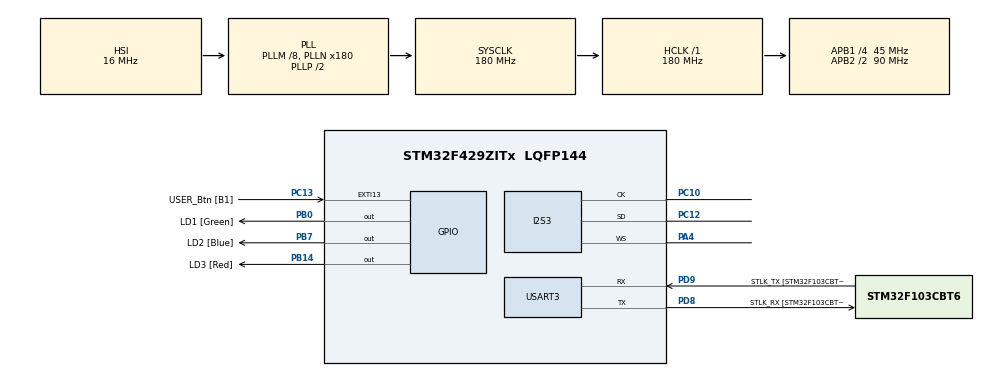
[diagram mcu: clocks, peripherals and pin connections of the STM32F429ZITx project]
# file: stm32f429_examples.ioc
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Dma.Request0=SPI3_RX
Dma.SPI3_RX.0.Direction=DMA_PERIPH_TO_MEMORY
Dma.SPI3_RX.0.FIFOMode=DMA_FIFOMODE_DISABLE
Dma.SPI3_RX.0.Instance=DMA1_Stream0
Dma.SPI3_RX.0.MemDataAlignment=DMA_MDATAALIGN_HALFWORD
Dma.SPI3_RX.0.MemInc=DMA_MINC_ENABLE
Dma.SPI3_RX.0.Mode=DMA_CIRCULAR
Dma.SPI3_RX.0.PeriphDataAlignment=DMA_PDATAALIGN_HALFWORD
Dma.SPI3_RX.0.PeriphInc=DMA_PINC_DISABLE
Dma.SPI3_RX.0.Priority=DMA_PRIORITY_LOW
I2S3.AudioFreq=I2S_AUDIOFREQ_48K
I2S3.CPOL=I2S_CPOL_HIGH
I2S3.DataFormat=I2S_DATAFORMAT_24B
I2S3.ErrorAudioFreq=-0.79 %
I2S3.FullDuplexMode=I2S_FULLDUPLEXMODE_DISABLE
I2S3.Instance=SPI$Index
I2S3.Mode=I2S_MODE_MASTER_RX
I2S3.RealAudioFreq=47.619 KHz
I2S3.VirtualMode=I2S_MODE_MASTER
Mcu.Family=STM32F4
Mcu.Name=STM32F429ZITx
Mcu.Package=LQFP144
NVIC.DMA1_Stream0_IRQn=true\:0\:0\:false\:false\:true\:false\:true\:true
NVIC.PriorityGroup=NVIC_PRIORITYGROUP_4
PA13.GPIO_Label=TMS
PA13.Mode=Serial_Wire
PA13.Signal=SYS_JTMS-SWDIO
PA14.GPIO_Label=TCK
PA14.Mode=Serial_Wire
PA14.Signal=SYS_JTCK-SWCLK
PA4.Mode=Half_Duplex_Master
PA4.Signal=I2S3_WS
PB0.GPIO_Label=LD1 [Green]
PB0.Signal=GPIO_Output
PB14.GPIO_Label=LD3 [Red]
PB14.Signal=GPIO_Output
PB7.GPIO_Label=LD2 [Blue]
PB7.Signal=GPIO_Output
PC10.Mode=Half_Duplex_Master
PC10.Signal=I2S3_CK
PC12.Mode=Half_Duplex_Master
PC12.Signal=I2S3_SD
PC13.GPIO_Label=USER_Btn [B1]
PC13.Signal=GPXTI13
PC14/OSC32_IN.Mode=LSE-External-Oscillator
PC14/OSC32_IN.Signal=RCC_OSC32_IN
PC15/OSC32_OUT.Mode=LSE-External-Oscillator
PC15/OSC32_OUT.Signal=RCC_OSC32_OUT
PD8.GPIO_Label=STLK_RX [STM32F103CBT6_PA3]
PD8.Mode=Asynchronous
PD8.Signal=USART3_TX
PD9.GPIO_Label=STLK_TX [STM32F103CBT6_PA2]
PD9.Mode=Asynchronous
PD9.Signal=USART3_RX
PH0/OSC_IN.Mode=HSE-External-Oscillator
PH0/OSC_IN.Signal=RCC_OSC_IN
PH1/OSC_OUT.Mode=HSE-External-Oscillator
PH1/OSC_OUT.Signal=RCC_OSC_OUT
ProjectManager.HeapSize=0x200
ProjectManager.StackSize=0x400
ProjectManager.TargetToolchain=Makefile
RCC.48MHZClocksFreq_Value=90000000
RCC.AHBFreq_Value=180000000
RCC.APB1CLKDivider=RCC_HCLK_DIV4
RCC.APB1Freq_Value=45000000
RCC.APB1TimFreq_Value=90000000
RCC.APB2CLKDivider=RCC_HCLK_DIV2
RCC.APB2Freq_Value=90000000
RCC.APB2TimFreq_Value=180000000
RCC.CortexFreq_Value=180000000
RCC.HCLKFreq_Value=180000000
RCC.HSE_VALUE=8000000
RCC.HSI_VALUE=16000000
RCC.PLLM=8
RCC.PLLMUL=RCC_PLL_MUL9
RCC.PLLN=180
RCC.PRESCALERUSB=RCC_USBCLKSOURCE_PLL_DIV1_5
RCC.SYSCLKFreq_VALUE=180000000
RCC.SYSCLKSource=RCC_SYSCLKSOURCE_PLLCLK
RCC.SYSCLKSourceVirtual=RCC_SYSCLKSOURCE_PLLCLK
RCC.USBFreq_Value=48000000
RCC.VCOOutputFreq_Value=360000000
USART3.VirtualMode=VM_ASYNC
board=NUCLEO-F429ZI

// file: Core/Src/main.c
/* USER CODE BEGIN Header */
/**
 ******************************************************************************
 * @file           : main.c
 * @brief          : Main program body
 ******************************************************************************
 * @attention
 *
 * Copyright (c) 2022 STMicroelectronics.
 * All rights reserved.
 *
 * This software is licensed under terms that can be found in the LICENSE file
 * in the root directory of this software component.
 * If no LICENSE file comes with this software, it is provided AS-IS.
 *
 ******************************************************************************
 */
/* USER CODE END Header */
#include "main.h"
#include "dma.h"
#include "i2s.h"
#include "usart.h"
#include "gpio.h"

void SystemClock_Config(void);

/* USER CODE BEGIN 0 */
void STM32_HAL_Init(void)
{

    /* Reset of all peripherals, Initializes the Flash interface and the Systick.
     */
    HAL_Init();
    SystemClock_Config();
    MX_GPIO_Init();
    MX_DMA_Init();
    MX_USART3_UART_Init();
    MX_I2S3_Init();
}
/* USER CODE END 0 */

void SystemClock_Config(void)
{
  RCC_OscInitTypeDef RCC_OscInitStruct = {0};
  RCC_ClkInitTypeDef RCC_ClkInitStruct = {0};

  /** Configure the main internal regulator output voltage
  */
  __HAL_RCC_PWR_CLK_ENABLE();
  __HAL_PWR_VOLTAGESCALING_CONFIG(PWR_REGULATOR_VOLTAGE_SCALE1);

  /** Initializes the RCC Oscillators according to the specified parameters
  * in the RCC_OscInitTypeDef structure.
  */
  RCC_OscInitStruct.OscillatorType = RCC_OSCILLATORTYPE_HSI;
  RCC_OscInitStruct.HSIState = RCC_HSI_ON;
  RCC_OscInitStruct.HSICalibrationValue = RCC_HSICALIBRATION_DEFAULT;
  RCC_OscInitStruct.PLL.PLLState = RCC_PLL_ON;
  RCC_OscInitStruct.PLL.PLLSource = RCC_PLLSOURCE_HSI;
  RCC_OscInitStruct.PLL.PLLM = 8;
  RCC_OscInitStruct.PLL.PLLN = 180;
  RCC_OscInitStruct.PLL.PLLP = RCC_PLLP_DIV2;
  RCC_OscInitStruct.PLL.PLLQ = 4;
  if (HAL_RCC_OscConfig(&RCC_OscInitStruct) != HAL_OK)
  {
    Error_Handler();
  }

  /** Activate the Over-Drive mode
  */
  if (HAL_PWREx_EnableOverDrive() != HAL_OK)
  {
    Error_Handler();
  }

  /** Initializes the CPU, AHB and APB buses clocks
  */
  RCC_ClkInitStruct.ClockType = RCC_CLOCKTYPE_HCLK|RCC_CLOCKTYPE_SYSCLK
                              |RCC_CLOCKTYPE_PCLK1|RCC_CLOCKTYPE_PCLK2;
  RCC_ClkInitStruct.SYSCLKSource = RCC_SYSCLKSOURCE_PLLCLK;
  RCC_ClkInitStruct.AHBCLKDivider = RCC_SYSCLK_DIV1;
  RCC_ClkInitStruct.APB1CLKDivider = RCC_HCLK_DIV4;
  RCC_ClkInitStruct.APB2CLKDivider = RCC_HCLK_DIV2;

  if (HAL_RCC_ClockConfig(&RCC_ClkInitStruct, FLASH_LATENCY_5) != HAL_OK)
  {
    Error_Handler();
  }
}

void Error_Handler(void)
{
    __disable_irq();
    while (1) {
    }
}

#ifdef  USE_FULL_ASSERT
/**
  * @brief  Reports the name of the source file and the source line number
  *         where the assert_param error has occurred.
  * @param  file: pointer to the source file name
  * @param  line: assert_param error line source number
  * @retval None
  */
void assert_failed(uint8_t *file, uint32_t line)
{
  /* USER CODE BEGIN 6 */
    /* User can add his own implementation to report the file name and line
       number, ex: printf("Wrong parameters value: file %s on line %d\r\n", file,
       line) */
  /* USER CODE END 6 */
}
#endif /* USE_FULL_ASSERT */
